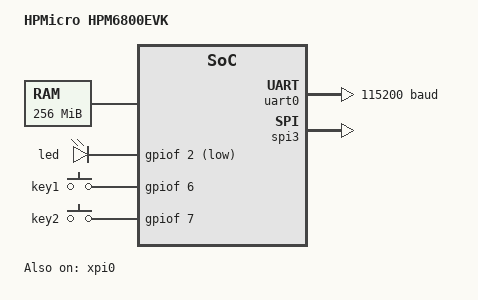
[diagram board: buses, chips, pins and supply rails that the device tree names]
/*
 * Copyright 2024 HPMicro
 * SPDX-License-Identifier: Apache-2.0
 */

/dts-v1/;

#include <hpmicro/hpm6880.dtsi>
#include "hpm6800evk-pinctrl.dtsi"

/ {
	model = "HPMicro HPM6800EVK";
	compatible = "HPMicro,hpm6800evk";

	aliases {
		led0 = &led;
		sw0 = &key1;
	};

	chosen {
		zephyr,console = &uart0;
		zephyr,shell-uart = &uart0;
		zephyr,sram = &sdram;
		zephyr,flash = &flash0;
		zephyr,code-partition = &slot0_partition;
	};

	ext_ram: memory@40000000 {
		device_type = "memory";
		reg = <0x40000000 DT_SIZE_M(256)>;
		#address-cells = <1>;
		#size-cells = <1>;
		sdram: memory@40000000 {
			reg = <0x40000000 DT_SIZE_M(224)>;
		};
		sdram_noncache: memory@4e000000 {
			reg = <0x4e000000 DT_SIZE_M(32)>;
		};
	};

	leds {
		compatible = "gpio-leds";
		led: led {
			gpios = <&gpiof 2 (GPIO_PULL_DOWN | GPIO_ACTIVE_LOW)>;
		};
	};

	gpio_keys {
		compatible = "gpio-keys";
		key1: key1 {
			gpios = <&gpiof 6 (GPIO_PULL_UP | GPIO_ACTIVE_HIGH)>;
		};
		key2: key2 {
			gpios = <&gpiof 7 (GPIO_PULL_UP | GPIO_ACTIVE_HIGH)>;
		};
	};
};

&hdma {
	status = "okay";
};

&xdma {
	status = "okay";
};

&uart0 {
	status = "okay";
	current-speed = <115200>;
	pinctrl-0 = <&pinmux_uart0>;
	pinctrl-names = "default";
	uart-idle-trgm-reg = <0xF022C000>;
	uart-idle-trgm-pin = <115>;
	uart-idle-trgm-input-src = <0x0B>;
	uart-idle-trgm-output-gptmr-in = <0x38>;
	uart-idle-trgm-output-gptmr-sync = <0x37>;
	uart-idle-gptmr-reg = <0xF0090000>;
	uart-idle-gptmr-clock-name = <CLOCK_GPTMR4>;
	dmas = <&hdma 0 8>, <&hdma 1 9>;
	dma-names = "rx", "tx";
};

&gpioe {
	pinctrl-0 = <&pinmux_gpioe>;
	pinctrl-names = "default";
	status = "okay";
};

&gpiof {
	pinctrl-0 = <&pinmux_gpiof>;
	pinctrl-names = "default";
	status = "okay";
};

&spi3 {
	status = "okay";
	pinctrl-0 = <&pinmux_spi3>;
	pinctrl-names = "default";
	cs-gpios = <&gpioe 4 GPIO_ACTIVE_LOW>;
	/* HDMA channels 0 and 1, muxed to SPI2 RX and TX */
	dmas = <&hdma 2 4>, <&hdma 3 5>;
	dma-names = "rx", "tx";
};

&xpi0 {
	status = "okay";
	flash0: flash@0 {
		compatible = "soc-nv-flash";
		reg = <0x80000000 DT_SIZE_M(16)>;
		status = "okay";
		erase-block-size = <4096>;
		write-block-size = <1>;
		
		partitions {
			compatible = "fixed-partitions";
			#address-cells = <1>;
			#size-cells = <1>;

			boot_partition: partition@0 {
				label = "mcuboot";
				reg = <0x0 0x3000>;
			};

			slot0_partition: partition@3000 {
				label = "image-0";
				reg = <0x3000 DT_SIZE_M(4)>;
			};
		};
	};
};
